# STM32WBA64 register map
File version: 1.1
CPU: CM33 r0p1, little endian, MPU, FPU, 4 interrupt priority bits
Registers are 32-bit, read-write, reset 0x0 unless marked. A register's access mark holds for its fields unless they carry their own. Offsets are from the block's base; [hi:lo] are bit positions; {n}, {i} and the like mark numbered series.

## GTZC_MPCBB1 — GTZC_MPCBB1 address block description
Base 0x40032C00
Same registers: GTZC_MPCBB2 0x40033000, SEC_GTZC_MPCBB1 0x50032C00, SEC_GTZC_MPCBB2 0x50033000
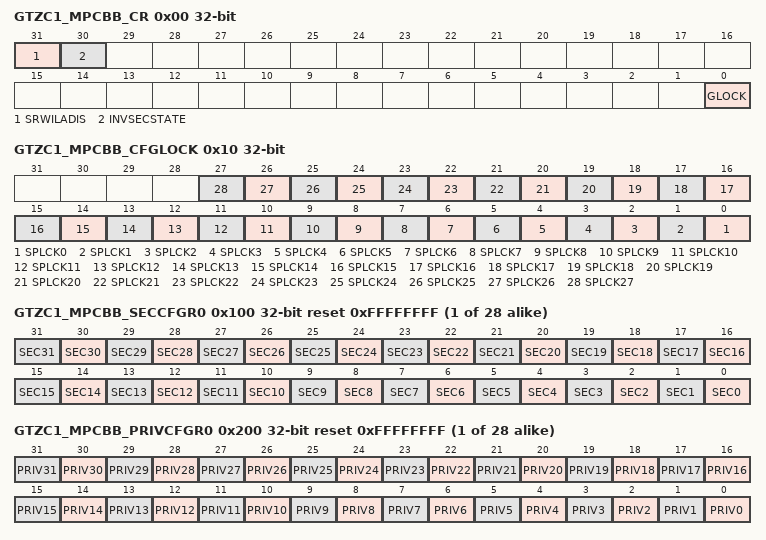
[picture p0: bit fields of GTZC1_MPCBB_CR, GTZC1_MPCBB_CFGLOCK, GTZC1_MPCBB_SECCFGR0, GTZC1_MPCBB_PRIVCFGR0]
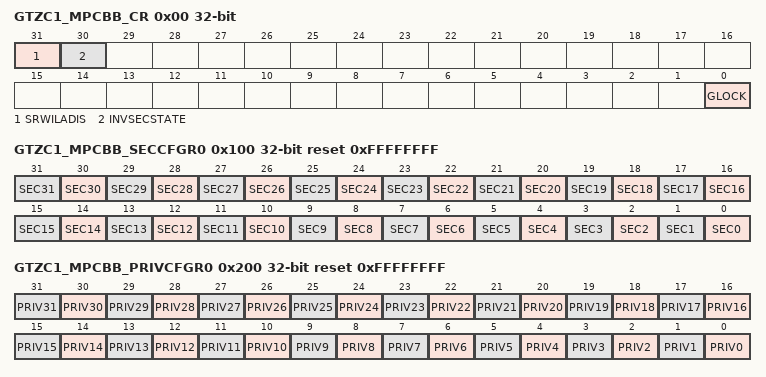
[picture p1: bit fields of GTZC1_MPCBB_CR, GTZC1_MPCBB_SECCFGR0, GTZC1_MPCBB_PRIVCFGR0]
0x00 GTZC1_MPCBB_CR (alternate view of GTZC1_TZSC_CR) — GTZC1 MPCBB control register
  [31] SRWILADIS — secure read/write illegal access disable
    0=enabled, secure read/write acces not allowed on Nonsecure SRAM block; 1=disabled, secure read/write access allowed on Nonsecure SRAM block
  [30] INVSECSTATE — SRAM clocks security state
    0=SRAM clock is secured if a secure area exists in the MPCBB; 1=SRAM clock is Nonsecure even if a secure area exists in the MPCBB, and secure even if no secure block is set in the MPCBB
  [0] GLOCK — Lock the control register of the MPCBB until next reset
    0=Control register not locked; 1=Control register locked
0x10 GTZC1_MPCBB_CFGLOCK (alternate view of GTZC1_TZSC_SECCFGR1) — GTZC1 MPCBB configuration lock register
  [all] fields
    0=GTZC1_MPCBB_SECCFGRn and GTZC1_MPCBB_PRIVCFGRn can be written; 1=Writes to GTZC1_MPCBB_SECCFGRn and GTZC1_MPCBB_PRIVCFGRn are ignored
  [n] SPLCK{n} (n=0..27) — Security/privilege configuration lock superblock
{0x100+4i} GTZC1_MPCBB_SECCFGR{i} reset 0xFFFFFFFF (i=0..27) — GTZC1 MPCBB security configuration for superblock {i} register
  [all] fields
    0=Nonsecure access only to block y, belonging to super-block n; 1=Secure access only to block y, belonging to super-block n
  [n] SEC{n} (n=0..31) — Security configuration for block y (y = 0 to 31) in super block n
{0x200+4i} GTZC1_MPCBB_PRIVCFGR{i} reset 0xFFFFFFFF (i=0..27) — GTZC1 MPCBB privileged configuration for superblock {i} register
  [all] fields
    0=Privileged and unprivileged access to block y, belonging to super-block n; 1=Only privileged access to block y, belonging to super-block n
  [n] PRIV{n} (n=0..31) — Privileged configuration for block y (y = 0 to 31), belonging to super-block n.

## GTZC_MPCBB6 — GTZC_MPCBB6 address block description
Base 0x40034000
Same registers: SEC_GTZC_MPCBB6 0x50034000
0x00 GTZC1_MPCBB_CR (alternate view of GTZC1_TZSC_CR) — GTZC1 MPCBB control register
  [31] SRWILADIS — secure read/write illegal access disable
    0=enabled, secure read/write acces not allowed on Nonsecure SRAM block; 1=disabled, secure read/write access allowed on Nonsecure SRAM block
  [30] INVSECSTATE — SRAM clocks security state
    0=SRAM clock is secured if a secure area exists in the MPCBB; 1=SRAM clock is Nonsecure even if a secure area exists in the MPCBB, and secure even if no secure block is set in the MPCBB
  [0] GLOCK — Lock the control register of the MPCBB until next reset
    0=Control register not locked; 1=Control register locked
0x10 GTZC1_MPCBB_CFGLOCK (alternate view of GTZC1_TZSC_SECCFGR1) — GTZC1 MPCBB configuration lock register
  [0] SPLCK0 — Security/privilege configuration lock superblock
    0=GTZC1_MPCBB_SECCFGRn and GTZC1_MPCBB_PRIVCFGRn can be written; 1=Writes to GTZC1_MPCBB_SECCFGRn and GTZC1_MPCBB_PRIVCFGRn are ignored
0x100 GTZC1_MPCBB_SECCFGR0 reset 0xFFFFFFFF — GTZC1 MPCBB security configuration for superblock 0 register
  [all] fields
    0=Nonsecure access only to block y, belonging to super-block n; 1=Secure access only to block y, belonging to super-block n
  [n] SEC{n} (n=0..31) — Security configuration for block y (y = 0 to 31) in super block n
0x200 GTZC1_MPCBB_PRIVCFGR0 reset 0xFFFFFFFF — GTZC1 MPCBB privileged configuration for superblock 0 register
  [all] fields
    0=Privileged and unprivileged access to block y, belonging to super-block n; 1=Only privileged access to block y, belonging to super-block n
  [n] PRIV{n} (n=0..31) — Privileged configuration for block y (y = 0 to 31), belonging to super-block n.
